# HC32M413 register map
File version: 1.0
CPU: CM4 r0p1, little endian, MPU, FPU, 4 interrupt priority bits
Registers are 32-bit, read-write, reset 0x0 unless marked. A register's access mark holds for its fields unless they carry their own. Offsets are from the block's base; [hi:lo] are bit positions; {n}, {i} and the like mark numbered series.

## EFM
Base 0x40010400
0x00 FAPRT
  [15:0] FAPRT
0x04 FSTP
  [0] FSTP
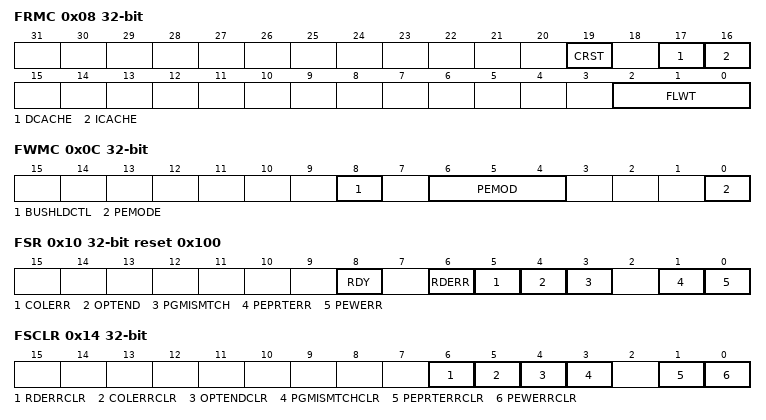
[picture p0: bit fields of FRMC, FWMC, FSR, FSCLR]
0x08 FRMC
  [19] CRST, [17] DCACHE, [16] ICACHE, [2:0] FLWT
0x0C FWMC
  [8] BUSHLDCTL, [6:4] PEMOD, [0] PEMODE
0x10 FSR ro reset 0x100
  [8] RDY, [6] RDERR, [5] COLERR, [4] OPTEND, [3] PGMISMTCH, [1] PEPRTERR, [0] PEWERR
0x14 FSCLR
  [6] RDERRCLR, [5] COLERRCLR, [4] OPTENDCLR, [3] PGMISMTCHCLR, [1] PEPRTERRCLR, [0] PEWERRCLR
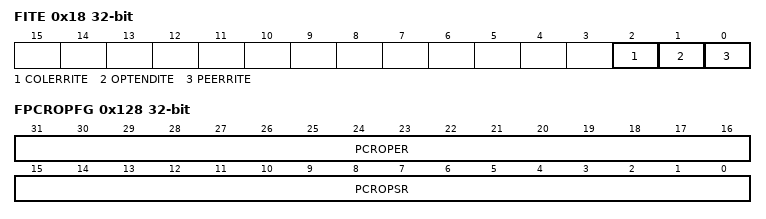
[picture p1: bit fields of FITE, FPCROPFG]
0x18 FITE
  [2] COLERRITE, [1] OPTENDITE, [0] PEERRITE
0x20 FPMTSW
  [17:0] FPMTSW
0x24 FPMTEW
  [17:0] FPMTEW
0x40 CHIPID ro reset 0x58480413
{0x50+4i} UQID{i} ro (i=0..2)
0x70 FOCDPRTFG ro
  [3] PCROPST
0x120 FCRCDOR ro
0x128 FPCROPFG ro
  [31:16] PCROPER, [15:0] PCROPSR
0x288 HRCCFGR 8-bit
  [2:0] HRCFREQS

## EMB0 — desc EMB
Base 0x40017C00
Same registers: EMB1 0x40017C20
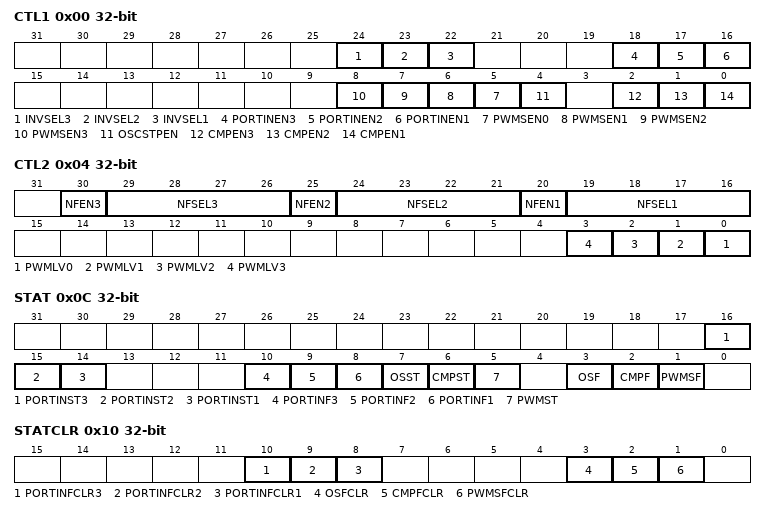
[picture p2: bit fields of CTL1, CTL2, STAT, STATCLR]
0x00 CTL1
  [24] INVSEL3, [23] INVSEL2, [22] INVSEL1, [18] PORTINEN3, [17] PORTINEN2, [16] PORTINEN1, [n+5] PWMSEN{n} (n=0..3), [4] OSCSTPEN, [2] CMPEN3, [1] CMPEN2, [0] CMPEN1
0x04 CTL2
  [30] NFEN3, [29:26] NFSEL3, [25] NFEN2, [24:21] NFSEL2, [20] NFEN1, [19:16] NFSEL1, [n] PWMLV{n} (n=0..3)
0x08 SOE
  [0] SOE
0x0C STAT ro
  [16] PORTINST3, [15] PORTINST2, [14] PORTINST1, [10] PORTINF3, [9] PORTINF2, [8] PORTINF1, [7] OSST, [6] CMPST, [5] PWMST, [3] OSF, [2] CMPF, [1] PWMSF
0x10 STATCLR wo
  [10] PORTINFCLR3, [9] PORTINFCLR2, [8] PORTINFCLR1, [3] OSFCLR, [2] CMPFCLR, [1] PWMSFCLR
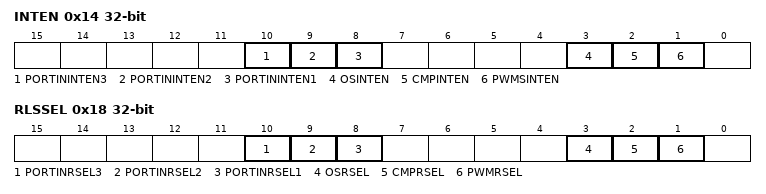
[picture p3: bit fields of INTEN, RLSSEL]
0x14 INTEN
  [10] PORTININTEN3, [9] PORTININTEN2, [8] PORTININTEN1, [3] OSINTEN, [2] CMPINTEN, [1] PWMSINTEN
0x18 RLSSEL
  [10] PORTINRSEL3, [9] PORTINRSEL2, [8] PORTINRSEL1, [3] OSRSEL, [2] CMPRSEL, [1] PWMRSEL

## FCM
Base 0x40048400
0x00 LVR
  [15:0] LVR
0x04 UVR
  [15:0] UVR
0x08 CNTR ro
  [15:0] CNTR
0x0C STR
  [0] START
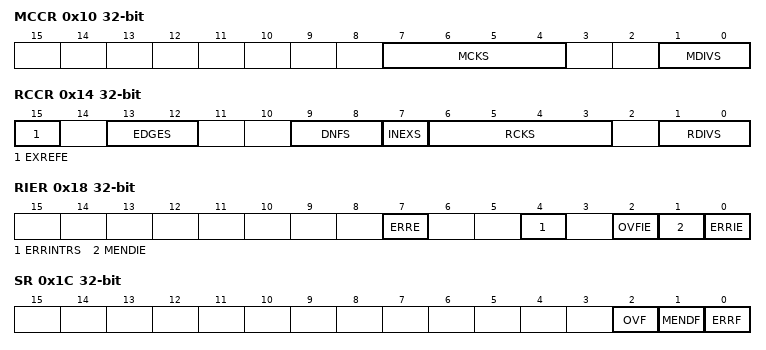
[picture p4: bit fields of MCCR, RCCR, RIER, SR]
0x10 MCCR
  [7:4] MCKS, [1:0] MDIVS
0x14 RCCR
  [15] EXREFE, [13:12] EDGES, [9:8] DNFS, [7] INEXS, [6:3] RCKS, [1:0] RDIVS
0x18 RIER
  [7] ERRE, [4] ERRINTRS, [2] OVFIE, [1] MENDIE, [0] ERRIE
0x1C SR ro
  [2] OVF, [1] MENDF, [0] ERRF
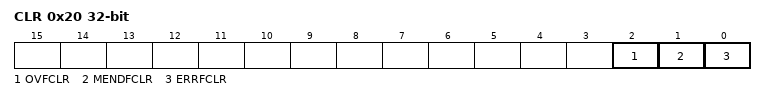
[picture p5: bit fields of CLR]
0x20 CLR wo
  [2] OVFCLR, [1] MENDFCLR, [0] ERRFCLR

## HALL
Base 0x4001E800
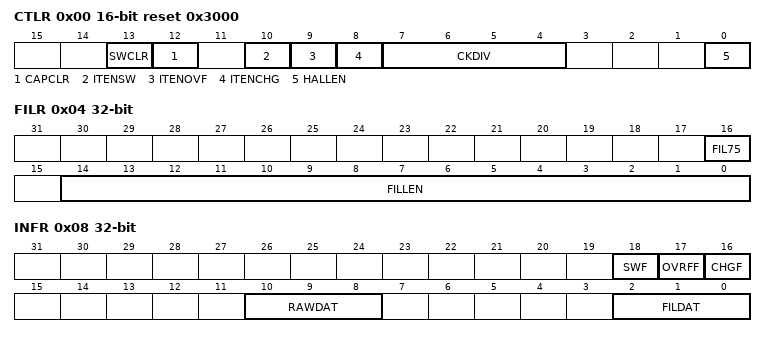
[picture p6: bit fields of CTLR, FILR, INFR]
0x00 CTLR 16-bit reset 0x3000
  [13] SWCLR, [12] CAPCLR, [10] ITENSW, [9] ITENOVF, [8] ITENCHG, [7:4] CKDIV, [0] HALLEN
0x04 FILR
  [16] FIL75, [14:0] FILLEN
0x08 INFR
  [18] SWF wo, [17] OVRFF, [16] CHGF, [10:8] RAWDAT ro, [2:0] FILDAT ro
0x10 CAPR ro
0x20 THDR reset 0xFFFFFFFF
0x30 CNTR

## I2C
Base 0x4004E000
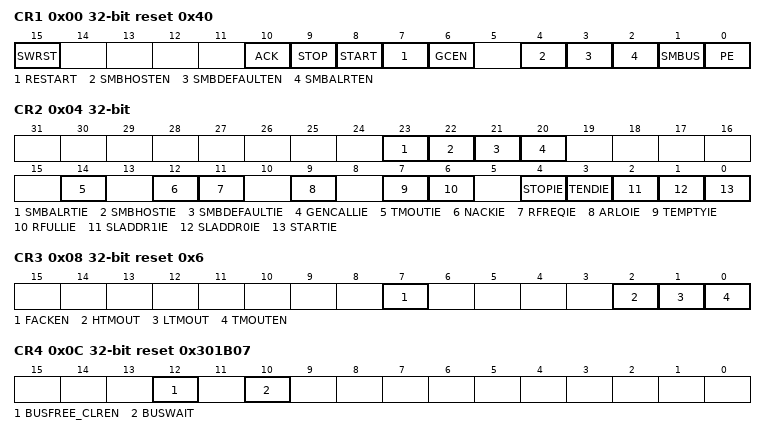
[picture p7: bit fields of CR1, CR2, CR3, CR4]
0x00 CR1 reset 0x40
  [15] SWRST, [10] ACK, [9] STOP, [8] START, [7] RESTART, [6] GCEN, [4] SMBHOSTEN, [3] SMBDEFAULTEN, [2] SMBALRTEN, [1] SMBUS, [0] PE
0x04 CR2
  [23] SMBALRTIE, [22] SMBHOSTIE, [21] SMBDEFAULTIE, [20] GENCALLIE, [14] TMOUTIE, [12] NACKIE, [11] RFREQIE, [9] ARLOIE, [7] TEMPTYIE, [6] RFULLIE, [4] STOPIE, [3] TENDIE, [2] SLADDR1IE, [1] SLADDR0IE, [0] STARTIE
0x08 CR3 reset 0x6
  [7] FACKEN, [2] HTMOUT, [1] LTMOUT, [0] TMOUTEN
0x0C CR4 reset 0x301B07
  [12] BUSFREE_CLREN, [10] BUSWAIT
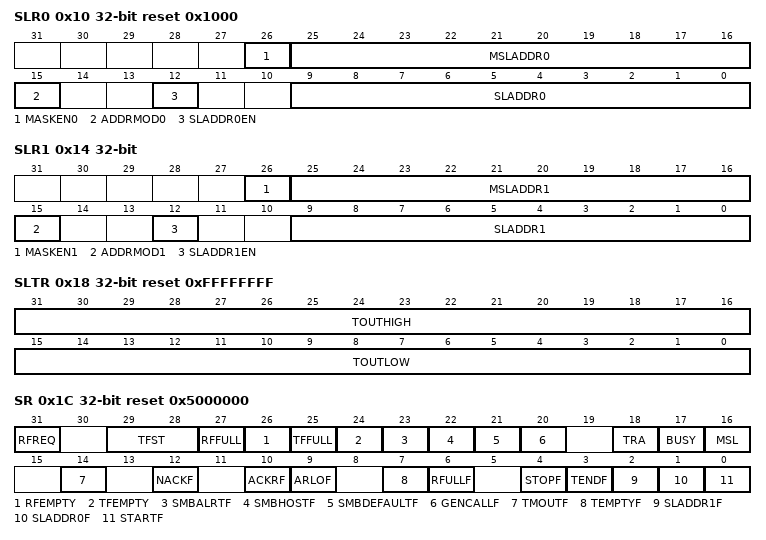
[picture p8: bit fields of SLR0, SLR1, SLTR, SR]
0x10 SLR0 reset 0x1000
  [26] MASKEN0, [25:16] MSLADDR0, [15] ADDRMOD0, [12] SLADDR0EN, [9:0] SLADDR0
0x14 SLR1
  [26] MASKEN1, [25:16] MSLADDR1, [15] ADDRMOD1, [12] SLADDR1EN, [9:0] SLADDR1
0x18 SLTR reset 0xFFFFFFFF
  [31:16] TOUTHIGH, [15:0] TOUTLOW
0x1C SR reset 0x5000000
  [31] RFREQ ro, [29:28] TFST ro, [27] RFFULL ro, [26] RFEMPTY ro, [25] TFFULL ro, [24] TFEMPTY ro, [23] SMBALRTF ro, [22] SMBHOSTF ro, [21] SMBDEFAULTF ro, [20] GENCALLF ro, [18] TRA, [17] BUSY ro, [16] MSL, [14] TMOUTF ro, [12] NACKF ro, [10] ACKRF ro, [9] ARLOF ro, [7] TEMPTYF ro, [6] RFULLF ro, [4] STOPF ro, [3] TENDF ro, [2] SLADDR1F ro, [1] SLADDR0F ro, [0] STARTF ro
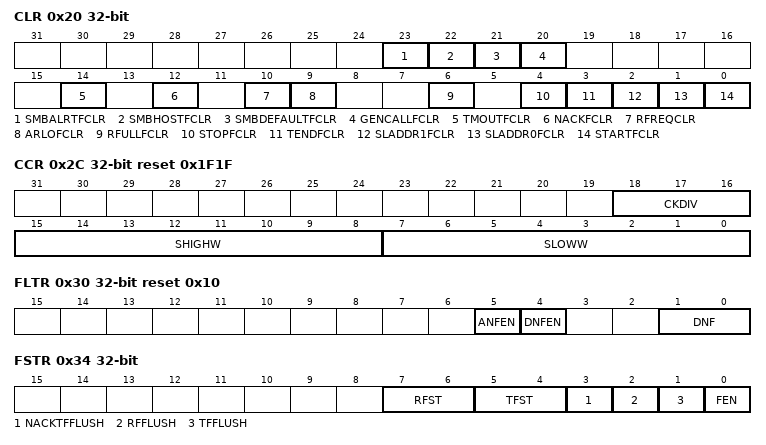
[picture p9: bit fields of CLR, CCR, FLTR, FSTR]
0x20 CLR wo
  [23] SMBALRTFCLR, [22] SMBHOSTFCLR, [21] SMBDEFAULTFCLR, [20] GENCALLFCLR, [14] TMOUTFCLR, [12] NACKFCLR, [10] RFREQCLR, [9] ARLOFCLR, [6] RFULLFCLR, [4] STOPFCLR, [3] TENDFCLR, [2] SLADDR1FCLR, [1] SLADDR0FCLR, [0] STARTFCLR
0x24 DTR 8-bit reset 0xFF
0x28 DRR 8-bit ro
0x2C CCR reset 0x1F1F
  [18:16] CKDIV, [15:8] SHIGHW, [7:0] SLOWW
0x30 FLTR reset 0x10
  [5] ANFEN, [4] DNFEN, [1:0] DNF
0x34 FSTR
  [7:6] RFST, [5:4] TFST, [3] NACKTFFLUSH, [2] RFFLUSH, [1] TFFLUSH, [0] FEN
0x38 SLVADDR
  [9:0] SLVADRR
